# MDR1206AFI register map
Vendor: Milandr; File version: 2.0
CPU: BM-310S0, little endian
Registers are 32-bit, read-write, reset 0x0 unless marked. A register's access mark holds for its fields unless they carry their own. Offsets are from the block's base; [hi:lo] are bit positions; {n}, {i} and the like mark numbered series.

## RST_CLK — RST_CLK description
Base 0x50020000
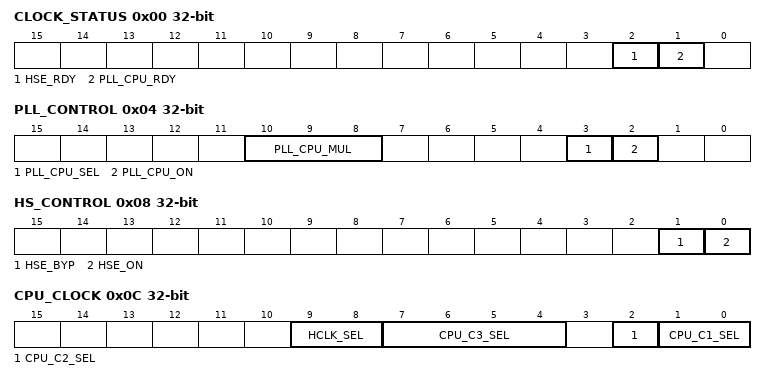
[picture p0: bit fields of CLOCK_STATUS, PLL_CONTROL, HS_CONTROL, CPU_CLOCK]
0x00 CLOCK_STATUS — Status Register of Clock Control Unit
  [2] HSE_RDY — "HSE is in the working mode" flag
  [1] PLL_CPU_RDY — "PLL is in the working mode" flag
0x04 PLL_CONTROL
  [10:8] PLL_CPU_MUL — Multiplication factor for CPU PLL
  [3] PLL_CPU_SEL — Selects PLL input frequency
  [2] PLL_CPU_ON — Enables PLL
0x08 HS_CONTROL — High Speed Oscillator Control Register
  [1] HSE_BYP — Selects oscillator or external generator
  [0] HSE_ON — Enables HSE
0x0C CPU_CLOCK — CPU Clock Control Register
  [9:8] HCLK_SEL — Selects the source fo HCLK
    0=HSI; 1=CPU_C3; 2=LSE; 3=LSI
  [7:4] CPU_C3_SEL — Selects the divisor for CPU_C2 to produce CPU_C3
  [2] CPU_C2_SEL — Selects the source clock for CPU_C2
    0=CPU_C1; 1=PLLCPUo
  [1:0] CPU_C1_SEL — Selects the source clock for CPU_C1
    0=HSI; 1=HSI/2; 2=HSE; 3=HSE/2
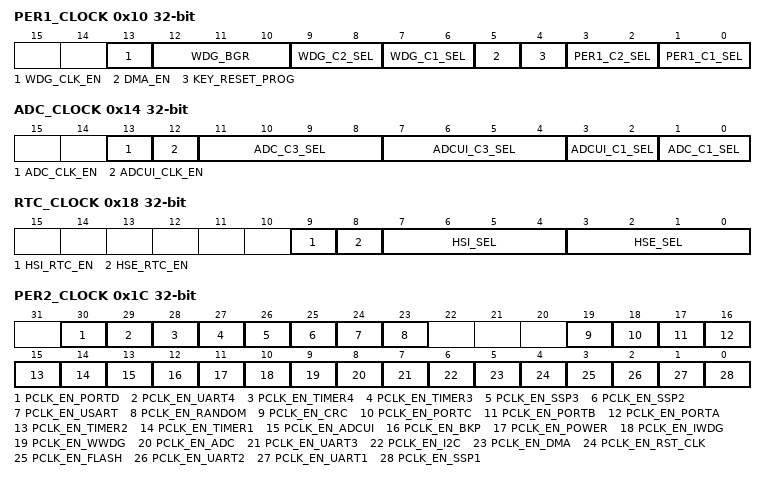
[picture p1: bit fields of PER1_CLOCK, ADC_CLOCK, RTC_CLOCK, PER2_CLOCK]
0x10 PER1_CLOCK — Peripheral Units Clock Control Register 1
  [13] WDG_CLK_EN — Enables WDG clocking
  [12:10] WDG_BGR — Selects the divisor of the WDG clock
  [9:8] WDG_C2_SEL — Selects the source clock for WDG_C2
    0=CPU_C1; 1=WDG_C1; 2=PLLCPUo; 3=HSI_C1
  [7:6] WDG_C1_SEL — Selects the source clock for WDG_C1
    0=LSI; 1=LSI/2; 2=LSE; 3=LSE/2
  [5] DMA_EN — Enables DMA clocking
  [4] KEY_RESET_PROG — Resets the memory of the unique keys
  [3:2] PER1_C2_SEL — Selects the source clock for PER_C2
    0=CPU_C1; 1=PER1_C1; 2=PLLCPUo; 3=HSI_C1
  [1:0] PER1_C1_SEL — Selects the source clock for PER_C1
    0=LSI; 1=LSI/2; 2=LSE; 3=LSE/2
0x14 ADC_CLOCK — ADC and ADCUI Clock Control Register
  [13] ADC_CLK_EN — Enables ADC clocking
  [12] ADCUI_CLK_EN — Enables ADCUI clocking
  [11:8] ADC_C3_SEL — Selects the divisor of ADC_C1 to produce ADCUI_C3
  [7:4] ADCUI_C3_SEL — Selects the divisor of ADCUI_C1 to produce ADCUI_C3
  [3:2] ADCUI_C1_SEL — Selects the source clock for ADCUI_C1
    0=CPU; 1=PER1_C1; 2=PLLCPUo; 3=HSE_C1
  [1:0] ADC_C1_SEL — Selects the source clock for ADC_C1
    0=CPU; 1=PER1_C1; 2=PLLCPUo; 3=HSE_C1
0x18 RTC_CLOCK — RTC Clock Control Register
  [9] HSI_RTC_EN — Enables RTC clocking with HSI
  [8] HSE_RTC_EN — Enables RTC clocking with HSE
  [7:4] HSI_SEL — Selects the divisor of HSI to produce HSI_C1
  [3:0] HSE_SEL — Selects the divisor of HSE to produce HSE_C1
0x1C PER2_CLOCK — Peripheral Units Clock Control Register 2
  [30] PCLK_EN_PORTD — Enables clocking of the PORTD
  [29] PCLK_EN_UART4 — Enables clocking of the UART4
  [28] PCLK_EN_TIMER4 — Enables clocking of the TIMER4
  [27] PCLK_EN_TIMER3 — Enables clocking of the TIMER3
  [26] PCLK_EN_SSP3 — Enables clocking of the SSP3
  [25] PCLK_EN_SSP2 — Enables clocking of the SSP2
  [24] PCLK_EN_USART — Enables clocking of the USART
  [23] PCLK_EN_RANDOM — Enables clocking of the Random Unit
  [19] PCLK_EN_CRC — Enables clocking of the CRC Calculation Unit
  [18] PCLK_EN_PORTC — Enables clocking of the PORTC
  [17] PCLK_EN_PORTB — Enables clocking of the PORTB
  [16] PCLK_EN_PORTA — Enables clocking of the PORTA
  [15] PCLK_EN_TIMER2 — Enables clocking of the TIMER2
  [14] PCLK_EN_TIMER1 — Enables clocking of the TIMER1
  [13] PCLK_EN_ADCUI — Enables clocking of the ADCUI
  [12] PCLK_EN_BKP — Enables clocking of the BKP
  [11] PCLK_EN_POWER — Enables clocking of the POWER Control Unit
  [10] PCLK_EN_IWDG — Enables clocking of the IWDG
  [9] PCLK_EN_WWDG — Enables clocking of the WWDG
  [8] PCLK_EN_ADC — Enables clocking of the ADC
  [7] PCLK_EN_UART3 — Enables clocking of the UART3
  [6] PCLK_EN_I2C — nables clocking of the I2C
  [5] PCLK_EN_DMA — Enables clocking of the DMA
  [4] PCLK_EN_RST_CLK — Enables clocking of the RST_CLK
  [3] PCLK_EN_FLASH — Enables clocking of the FLASH
  [2] PCLK_EN_UART2 — Enables clocking of the UART2
  [1] PCLK_EN_UART1 — Enables clocking of the UART1
  [0] PCLK_EN_SSP1 — Enables clocking of the SSP1
0x20 DMA_DONE_STICK — Fixes DMA_DONE signals
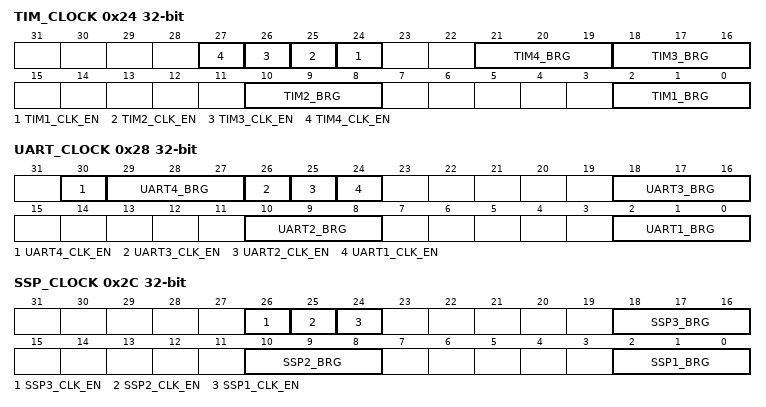
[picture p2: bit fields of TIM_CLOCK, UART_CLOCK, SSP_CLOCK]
0x24 TIM_CLOCK — Controls Timer clocking
  [n+23] TIM{n}_CLK_EN (n=1..4) — Enables clocking for TIM{n}
  [21:19] TIM4_BRG — TIM4 prescaler
  [18:16] TIM3_BRG — TIM3 prescaler
  [10:8] TIM2_BRG — TIM2 prescaler
  [2:0] TIM1_BRG — TIM1 prescaler
0x28 UART_CLOCK
  [30] UART4_CLK_EN — Enables clocking for UART4
  [29:27] UART4_BRG — UART4 prescaler
  [26] UART3_CLK_EN — Enables clocking for UART3
  [25] UART2_CLK_EN — Enables clocking for UART2
  [24] UART1_CLK_EN — Enables clocking for UART1
  [18:16] UART3_BRG — UART3 prescaler
  [10:8] UART2_BRG — UART2 prescaler
  [2:0] UART1_BRG — UART1 prescaler
0x2C SSP_CLOCK
  [26] SSP3_CLK_EN — Enables clocking for SSP3
  [25] SSP2_CLK_EN — Enables clocking for SSP2
  [24] SSP1_CLK_EN — Enables clocking for SSP1
  [18:16] SSP3_BRG — SSP3 prescaler
  [10:8] SSP2_BRG — SSP2 prescaler
  [2:0] SSP1_BRG — SSP1 prescaler
0x30 DIV_SYS_TIM — System Timer Clock Divisor Register
  [7:0] DIV_SYS_TIM — CLK_TIMER_PULSE = HCLK/(DIV_SYS_TIM + 2)
